# STM32F303xE register map
File version: 1.0
Registers are 32-bit, read-write, reset 0x0 unless marked. A register's access mark holds for its fields unless they carry their own. Offsets are from the block's base; [hi:lo] are bit positions.

## I2C1 — Inter-integrated circuit
Base 0x40005400
Same registers: I2C2 0x40005800, I2C3 0x40007800
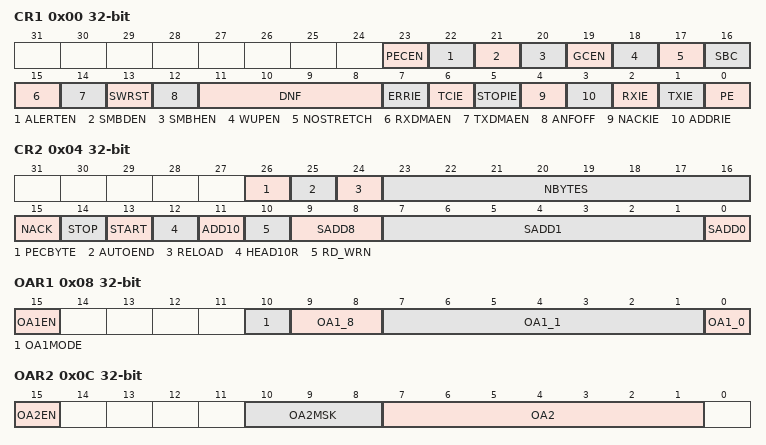
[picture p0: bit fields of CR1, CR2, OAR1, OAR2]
0x00 CR1 access per field — Control register 1
  [23] PECEN rw — PEC enable
  [22] ALERTEN rw — SMBUS alert enable
  [21] SMBDEN rw — SMBus Device Default address enable
  [20] SMBHEN rw — SMBus Host address enable
  [19] GCEN rw — General call enable
  [18] WUPEN rw — Wakeup from STOP enable
  [17] NOSTRETCH rw — Clock stretching disable
  [16] SBC rw — Slave byte control
  [15] RXDMAEN rw — DMA reception requests enable
  [14] TXDMAEN rw — DMA transmission requests enable
  [13] SWRST wo — Software reset
  [12] ANFOFF rw — Analog noise filter OFF
  [11:8] DNF rw — Digital noise filter
  [7] ERRIE rw — Error interrupts enable
  [6] TCIE rw — Transfer Complete interrupt enable
  [5] STOPIE rw — STOP detection Interrupt enable
  [4] NACKIE rw — Not acknowledge received interrupt enable
  [3] ADDRIE rw — Address match interrupt enable (slave only)
  [2] RXIE rw — RX Interrupt enable
  [1] TXIE rw — TX Interrupt enable
  [0] PE rw — Peripheral enable
0x04 CR2 — Control register 2
  [26] PECBYTE — Packet error checking byte
  [25] AUTOEND — Automatic end flightMode (master flightMode)
  [24] RELOAD — NBYTES reload flightMode
  [23:16] NBYTES — Number of bytes
  [15] NACK — NACK generation (slave flightMode)
  [14] STOP — Stop generation (master flightMode)
  [13] START — Start generation
  [12] HEAD10R — 10-bit address header only read direction (master receiver flightMode)
  [11] ADD10 — 10-bit addressing flightMode (master flightMode)
  [10] RD_WRN — Transfer direction (master flightMode)
  [9:8] SADD8 — Slave address bit 9:8 (master flightMode)
  [7:1] SADD1 — Slave address bit 7:1 (master flightMode)
  [0] SADD0 — Slave address bit 0 (master flightMode)
0x08 OAR1 — Own address register 1
  [15] OA1EN — Own Address 1 enable
  [10] OA1MODE — Own Address 1 10-bit flightMode
  [9:8] OA1_8 — Interface address
  [7:1] OA1_1 — Interface address
  [0] OA1_0 — Interface address
0x0C OAR2 — Own address register 2
  [15] OA2EN — Own Address 2 enable
  [10:8] OA2MSK — Own Address 2 masks
  [7:1] OA2 — Interface address
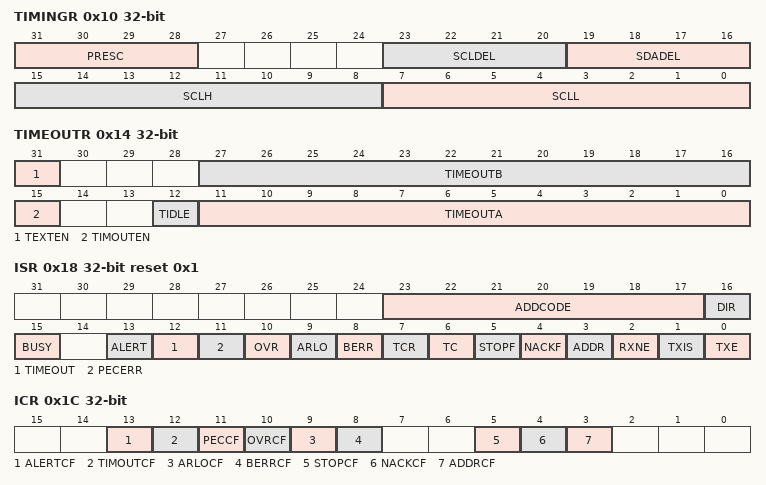
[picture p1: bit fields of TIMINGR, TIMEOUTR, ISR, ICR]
0x10 TIMINGR — Timing register
  [31:28] PRESC — Timing prescaler
  [23:20] SCLDEL — Data setup time
  [19:16] SDADEL — Data hold time
  [15:8] SCLH — SCL high period (master flightMode)
  [7:0] SCLL — SCL low period (master flightMode)
0x14 TIMEOUTR — Status register 1
  [31] TEXTEN — Extended clock timeout enable
  [27:16] TIMEOUTB — Bus timeout B
  [15] TIMOUTEN — Clock timeout enable
  [12] TIDLE — Idle clock timeout detection
  [11:0] TIMEOUTA — Bus timeout A
0x18 ISR access per field reset 0x1 — Interrupt and Status register
  [23:17] ADDCODE ro — Address match code (Slave flightMode)
  [16] DIR ro — Transfer direction (Slave flightMode)
  [15] BUSY ro — Bus busy
  [13] ALERT ro — SMBus alert
  [12] TIMEOUT ro — Timeout or t_low detection flag
  [11] PECERR ro — PEC Error in reception
  [10] OVR ro — Overrun/Underrun (slave flightMode)
  [9] ARLO ro — Arbitration lost
  [8] BERR ro — Bus error
  [7] TCR ro — Transfer Complete Reload
  [6] TC ro — Transfer Complete (master flightMode)
  [5] STOPF ro — Stop detection flag
  [4] NACKF ro — Not acknowledge received flag
  [3] ADDR ro — Address matched (slave flightMode)
  [2] RXNE ro — Receive data register not empty (receivers)
  [1] TXIS rw — Transmit interrupt status (transmitters)
  [0] TXE rw — Transmit data register empty (transmitters)
0x1C ICR wo — Interrupt clear register
  [13] ALERTCF — Alert flag clear
  [12] TIMOUTCF — Timeout detection flag clear
  [11] PECCF — PEC Error flag clear
  [10] OVRCF — Overrun/Underrun flag clear
  [9] ARLOCF — Arbitration lost flag clear
  [8] BERRCF — Bus error flag clear
  [5] STOPCF — Stop detection flag clear
  [4] NACKCF — Not Acknowledge flag clear
  [3] ADDRCF — Address Matched flag clear
0x20 PECR ro — PEC register
  [7:0] PEC — Packet error checking register
0x24 RXDR ro — Receive data register
  [7:0] RXDATA — 8-bit receive data
0x28 TXDR — Transmit data register
  [7:0] TXDATA — 8-bit transmit data
